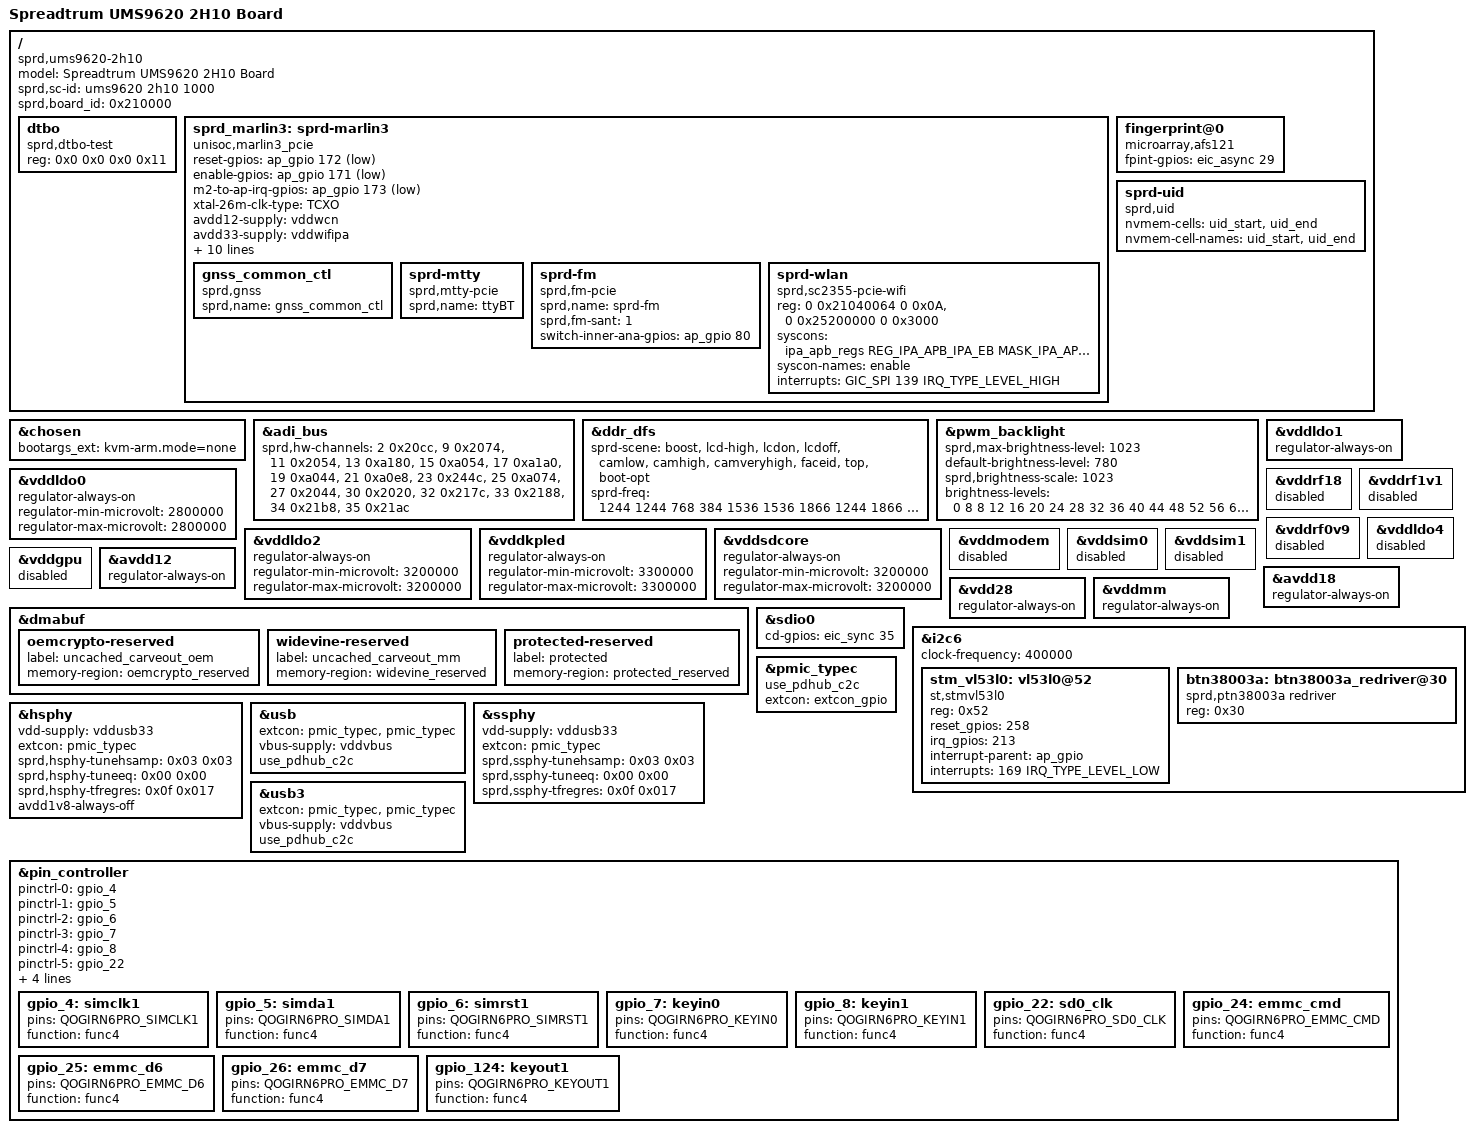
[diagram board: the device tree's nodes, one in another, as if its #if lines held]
// SPDX-License-Identifier: (Licenseref-Unisoc-General-1.0 OR GPL-2.0-only)
/*
 * ums9620-2h10-overlay.dts - Unisoc platform device
 *
 * Copyright 2022 Unisoc(Shanghai) Technologies Co.Ltd
 *
 * Licensed under the Unisoc General Software License, version 1.0 (the
 * License);
 * you may not use this file except in compliance with the License.
 * You may obtain a copy of the License at
 * https://www.unisoc.com/en_us/license/UNISOC_GENERAL_LICENSE_V1.0-EN_US
 * Software distributed under the License is distributed on an "AS IS" BASIS,
 * WITHOUT WARRANTIES OF ANY KIND, either express or implied.
 * See the Unisoc General Software License, version 1.0 for more details.
 *
 * Alternatively you can use and distribute this file under the terms of the
 * GNU General Public License version 2, provided that it has to be used
 *  (including but not limited to combining, linking) with any other file under
 * the GNU General Public License version 2 on platforms that use Unisoc Chips.
 */
#include <dt-bindings/wdv/wdv.h>

/dts-v1/;
/plugin/;
#include <dt-bindings/gpio/gpio.h>
#include <dt-bindings/interrupt-controller/arm-gic.h>
#include <dt-bindings/clock/sprd,ums9620-clk.h>
#include <dt-bindings/soc/sprd,qogirn6pro-regs.h>
#include <dt-bindings/soc/sprd,qogirn6pro-mask.h>
#include <dt-bindings/usb/pd.h>
#include "zte_lcd_lead_icnl9951r_hsd_10p95_fhd.dtsi"
#include "zte_lcd_lead_hx83102j_hsd_10p95_fhd.dtsi"
#include "zte_lcd_huaying_hx83102j_huaying_10p95_fhd.dtsi"
#include "zte_lcd_lectron_hx83102j_huaxing_10p95_fhd.dtsi"
#include "zte_lcd_lectron_hx83102j_huaxing_90hz_10p95_fhd.dtsi"
#include "zte_lcd_dijing_hx83102j_huaxing_10p95_fhd.dtsi"
#include "zte_lcd_dijing_ft8205p_longteng_10p95_fhd.dtsi"
#include "../../lcd/zte_lcd_dummy_mipi_cabc.dtsi"
#include "zte_lcd.dtsi"
#include "../../reserved-memory/ums9620-2h10-overlay.dtsi"
/* #include "../../sound/ums9620-overlay.dtsi" */  /*zte del for not use hdmi*/
#include <dt-bindings/mfd/sprd,ump9620-regs.h>
#include <dt-bindings/mfd/sprd,ump9620-mask.h>
#include <dt-bindings/input/input.h>
#include <dt-bindings/clock/sprd,ums9620-clk.h>
#include "../../wcn/wcn_modules.h"
#include "../../wcn/interface/wcn-sdio-register.dtsi"
#include "../../wcn/chip/wcn-marlin3lite-umw2652-register.dtsi"

/ {

	model = "Spreadtrum UMS9620 2H10 Board";

	compatible = "sprd,ums9620-2h10", "sprd,ums9620";

	sprd,sc-id = "ums9620 2h10 1000";

	sprd,board_id = <0x210000>; //XXYY00:base board,XXYY00~XXYYFF:customize board

	fragment {
		target-path = "/";
		__overlay__ {
			#address-cells = <2>;
			#size-cells = <2>;

			dtbo: dtbo {
				compatible = "sprd,dtbo-test";
				reg = <0x0 0x0 0x0 0x11>;
			};
			sprd_marlin3: sprd-marlin3 {
				compatible = "unisoc,marlin3_pcie";
				#address-cells = <2>;
				#size-cells = <2>;
				reset-gpios = <&ap_gpio 172 GPIO_ACTIVE_LOW>;
				enable-gpios = <&ap_gpio 171 GPIO_ACTIVE_LOW>;
				m2-to-ap-irq-gpios = <&ap_gpio 173 GPIO_ACTIVE_LOW>;
				xtal-26m-clk-type = "TCXO";

				avdd12-supply = <&vddwcn>;
				avdd33-supply = <&vddwifipa>;
				dcxo18-supply = <&vddsim2>;

				avdd12-parent-bound-chip = <REG_ANA_SLP_DCDC_PD_CTRL MASK_ANA_SLP_DCDCGEN1_PD_EN 0x0 MASK_ANA_SLP_DCDCGEN1_PD_EN>;

				clock-names = "clk_32k","source","enable";
				clocks = <&aonapb_gate CLK_AUX0>,
					 <&ext_32k>,
					 <&aonapb_gate CLK_AUX0_EB>;

				/* no need config dvdd12 because of share vddmem to DDR */
				/* ufs  download*/
				sprd,btwf-file-name = "/dev/block/by-name/wcnmodem";
				sprd,gnss-file-name = "/vendor/firmware/gnssmodem.bin";
				sprd,rc-ctrl = <&pcie1>;

				gnss_common_ctl {
					compatible = "sprd,gnss";
					sprd,name = "gnss_common_ctl";
				};

				sprd-mtty {
					compatible = "sprd,mtty-pcie";
					sprd,name = "ttyBT";
				};

				sprd-fm {
					compatible = "sprd,fm-pcie";
					sprd,name = "sprd-fm";
					sprd,fm-sant = <1>;
                                        switch-inner-ana-gpios = <&ap_gpio 80 0>; /*support lna switch */
				};

				sprd-wlan {
					compatible = "sprd,sc2355-pcie-wifi";
					reg = <0 0x21040064 0 0x0A>,
					<0 0x25200000 0 0x3000>;
					reg-names = "wifi_ipaqos",
							"pam_wifi_reg_base_remap";
					syscons = <&ipa_apb_regs
							REG_IPA_APB_IPA_EB
							MASK_IPA_APB_PAM_WIFI_EB>;
					syscon-names = "enable";
					interrupts = <GIC_SPI 139 IRQ_TYPE_LEVEL_HIGH>;
					interrupt-names = "pam-wifi-irq";
				};
			};

			fingerprint@0 {
				compatible = "microarray,afs121";
				fpint-gpios = <&eic_async 29 0>;
  			};

			sprd-uid {
				compatible = "sprd,uid";
				nvmem-cells = <&uid_start>, <&uid_end>;
				nvmem-cell-names = "uid_start", "uid_end";
			};

		};
	};
};

&chosen {
	bootargs_ext = "kvm-arm.mode=none";
};

&adi_bus {
	sprd,hw-channels = <2 0x20cc>, <9 0x2074>, <11 0x2054>, <13 0xa180>,
			<15 0xa054>, <17 0xa1a0>, <19 0xa044>, <21 0xa0e8>,
			<23 0x244c>, <25 0xa074>, <27 0x2044>, <30 0x2020>,
			<32 0x217c>, <33 0x2188>, <34 0x21b8>, <35 0x21ac>;
};

&ddr_dfs {
		sprd-scene = "boost", "lcd-high", "lcdon", "lcdoff", "camlow",
			"camhigh", "camveryhigh", "faceid", "top", "boot-opt";
		sprd-freq = <1244 1244 768 384 1536 1536 1866 1244 1866 1866>;
};

&pwm_backlight {
	sprd,max-brightness-level = <1023>;
	default-brightness-level = <780>;
	sprd,brightness-scale = <1023>;
	brightness-levels = <
					0   8  8  12  16  20
		24  28  32  36  40  44  48  52  56  60
		64  68  72  76  80  84  88  92  96  100
		104 108 112 116 120 124 128 132 136 140
		144 148 152 156 160 164 168 172 176 180
		184 188 192 196 200 204 208 212 216 220
		224 228 232 236 240 244 248 252 256 260
		264 268 272 276 280 284 288 292 296 300
		304 308 312 316 320 324 328 332 336 341
		345 349 353 357 361 365 369 373 377 381
		385 389 393 397 401 405 409 413 417 421
		425 429 433 437 441 445 449 453 457 461
		465 469 473 477 481 485 489 493 497 501
		505 509 513 517 521 525 529 533 537 541
		545 549 553 557 561 565 569 573 577 581
		585 589 593 597 601 605 609 613 617 621
		625 629 633 637 641 645 649 653 657 661
		665 669 673 677 682 686 690 694 698 702
		706 710 714 718 722 726 730 734 738 742
		746 750 754 758 762 766 770 774 778 782
		786 790 794 798 802 806 810 814 818 822
		826 830 834 838 842 846 850 854 858 862
		866 870 874 878 882 886 890 894 898 902
		906 910 914 918 922 926 930 934 938 942
		946 950 954 958 962 966 970 974 978 982
		986 990 994 998 1002 1006 1010 1014 1018 1023
	>;
};

/* enable vddldo0 for sub skey */
&vddldo0 {
	regulator-always-on;
	regulator-min-microvolt = <2800000>;
	regulator-max-microvolt = <2800000>;
};

&vddldo1 {
	regulator-always-on;
};

/* enable sensor vddldo2 for prx */
&vddldo2 {
	regulator-always-on;
	regulator-min-microvolt = <3200000>;
	regulator-max-microvolt = <3200000>;
};

/* enable als sensor vdd_als vddkpled */
&vddkpled {
	regulator-always-on;
	regulator-min-microvolt = <3300000>;
	regulator-max-microvolt = <3300000>;
};

&vddsdcore {
	regulator-always-on;
	regulator-min-microvolt = <3200000>;
	regulator-max-microvolt = <3200000>;
};

&vddrf18 {
	status = "disabled";
};

&vddrf1v1 {
	status = "disabled";
};

&vddrf0v9 {
	status = "disabled";
};

&vddldo4 {
	status = "disabled";
};

&vddmodem {
	status = "disabled";
};

&vddsim0 {
	status = "disabled";
};

&vddsim1 {
	status = "disabled";
};

&vddgpu {
	status = "disabled";
};

&avdd12 {
	regulator-always-on;
};

&avdd18 {
	regulator-always-on;
};

&vdd28 {
	regulator-always-on;
};

&vddmm {
	regulator-always-on;
};

&dmabuf {
#ifdef BSP_KERNEL_CONFIG_WIDEVINE_L1
	oemcrypto-reserved {
		label = "uncached_carveout_oem";
		memory-region = <&oemcrypto_reserved>;
	};

	widevine-reserved {
		label = "uncached_carveout_mm";
		memory-region = <&widevine_reserved>;
	};
#endif
	protected-reserved {
		label = "protected";
		memory-region = <&protected_reserved>;
	};
};

&sdio0 {
	cd-gpios = <&eic_sync 35 GPIO_ACTIVE_HIGH>;
};



&i2c6 {
	status = "okay";
	clock-frequency = <400000>;


	stm_vl53l0: vl53l0@52 {
		compatible = "st,stmvl53l0";
		reg = <0x52>;
		reset_gpios = <258>;
		irq_gpios = <213>;
		interrupt-parent = <&ap_gpio>;
		interrupts = <169 IRQ_TYPE_LEVEL_LOW>;
	};

	btn38003a: btn38003a_redriver@30 {
		compatible = "sprd,ptn38003a redriver";
		reg = <0x30>;
	};

};

&hsphy {
	vdd-supply = <&vddusb33>;
	extcon = <&pmic_typec>;
	/* first value is reserverd, the second is host */
	sprd,hsphy-tunehsamp = /bits/ 8 <0x03 0x03>;
	sprd,hsphy-tuneeq = /bits/ 8 <0x00 0x00>;
	sprd,hsphy-tfregres = /bits/ 8 <0x0f 0x017>;
	/* avdd1v8 always off */
	avdd1v8-always-off;
	status = "okay";
};

&usb {
	extcon = <&pmic_typec>, <&pmic_typec>;
	vbus-supply = <&vddvbus>;
	status = "okay";
	use_pdhub_c2c;
};

&ssphy {
	vdd-supply = <&vddusb33>;
	extcon = <&pmic_typec>;
	/* first value is device eye-patt setting, the second is host */
	sprd,ssphy-tunehsamp = /bits/ 8 <0x03 0x03>;
	sprd,ssphy-tuneeq = /bits/ 8 <0x00 0x00>;
	sprd,ssphy-tfregres = /bits/ 8 <0x0f 0x017>;
	status = "okay";
};

&usb3 {
	extcon = <&pmic_typec>, <&pmic_typec>;
	vbus-supply = <&vddvbus>;
	status = "okay";
	use_pdhub_c2c;
};

&pmic_typec {
	use_pdhub_c2c;
	extcon = <&extcon_gpio>;
	status = "okay";
};

&pin_controller {
	pinctrl-names =
	/* IM1_CLK ,SIM1_DA ,SIM1_RST ,keyin0 */
	 "gpio_4", "gpio_5", "gpio_6", "gpio_7",
	/* keyin1 ,sd0_clk, emmc_cmd */
	"gpio_8", "gpio_22", "gpio_24",
	/* emmc_d6, emmc_d7, emmc_d7 */
	"gpio_25", "gpio_26", "gpio_124";

	pinctrl-0 = <&gpio_4>;
	pinctrl-1 = <&gpio_5>;
	pinctrl-2 = <&gpio_6>;
	pinctrl-3 = <&gpio_7>;
	pinctrl-4 = <&gpio_8>;
	pinctrl-5 = <&gpio_22>;
	pinctrl-6 = <&gpio_24>;
	pinctrl-7 = <&gpio_25>;
	pinctrl-8 = <&gpio_26>;
	pinctrl-9 = <&gpio_124>;

	gpio_4: simclk1 {
		pins = "QOGIRN6PRO_SIMCLK1";
		function = "func4";
	};

	gpio_5: simda1 {
		pins = "QOGIRN6PRO_SIMDA1";
		function = "func4";
	};

	gpio_6: simrst1 {
		pins = "QOGIRN6PRO_SIMRST1";
		function = "func4";
	};

	gpio_7: keyin0 {
		pins = "QOGIRN6PRO_KEYIN0";
		function = "func4";
	};

	gpio_8: keyin1 {
		pins = "QOGIRN6PRO_KEYIN1";
		function = "func4";
	};

	gpio_22: sd0_clk {
		pins = "QOGIRN6PRO_SD0_CLK";
		function = "func4";
	};

	gpio_24: emmc_cmd {
		pins = "QOGIRN6PRO_EMMC_CMD";
		function = "func4";
	};

	gpio_25: emmc_d6 {
		pins = "QOGIRN6PRO_EMMC_D6";
		function = "func4";
	};

	gpio_26: emmc_d7 {
		pins = "QOGIRN6PRO_EMMC_D7";
		function = "func4";
	};

	gpio_124: keyout1 {
		pins = "QOGIRN6PRO_KEYOUT1";
		function = "func4";
	};
};

